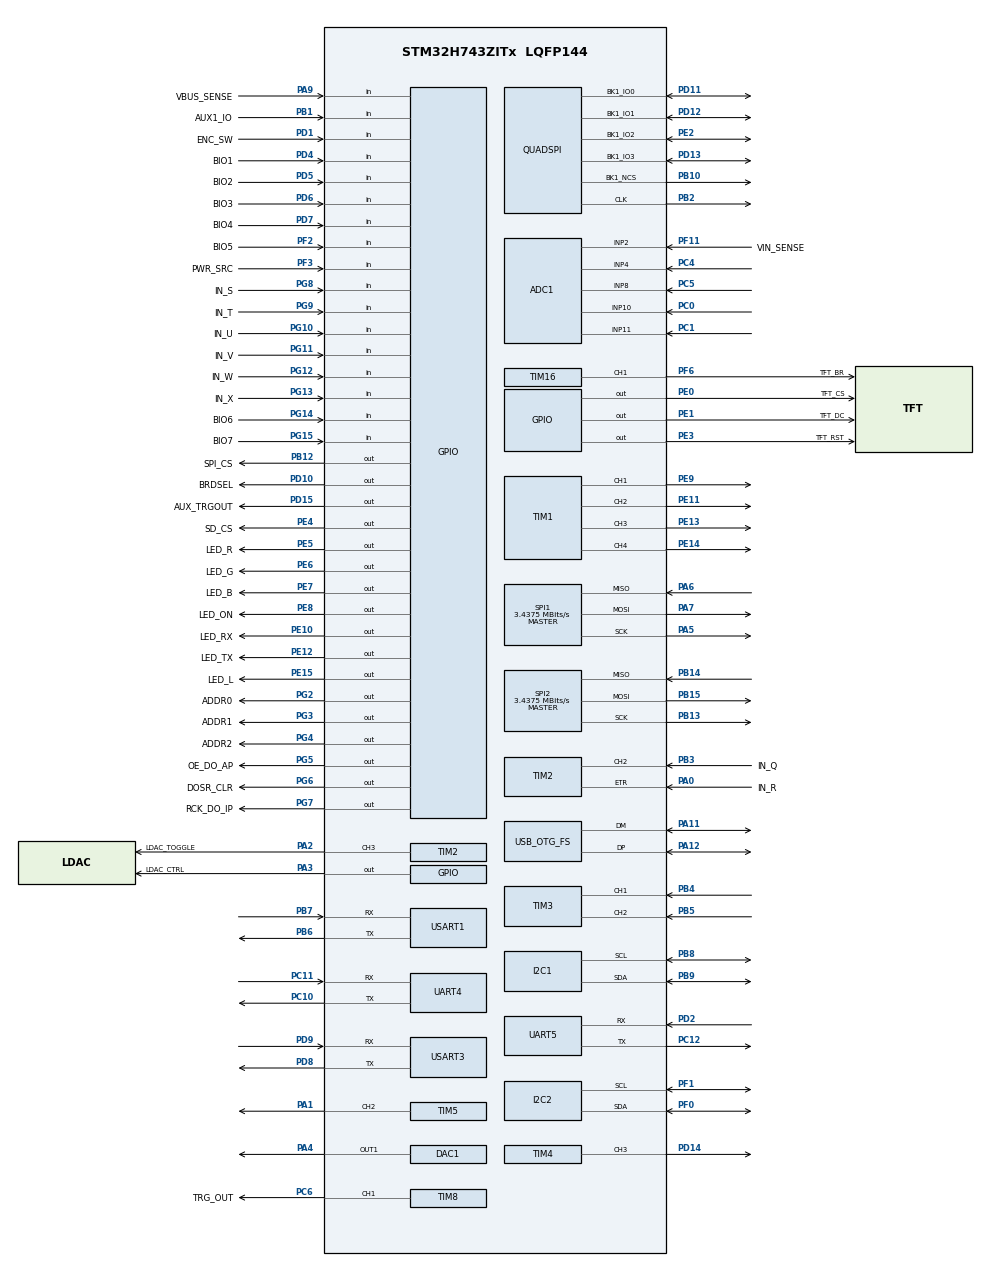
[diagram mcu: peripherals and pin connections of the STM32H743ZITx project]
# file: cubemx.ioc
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ADC1.Channel-1\#ChannelRegularConversion=ADC_CHANNEL_10
ADC1.Channel-2\#ChannelRegularConversion=ADC_CHANNEL_11
ADC1.Channel-3\#ChannelRegularConversion=ADC_CHANNEL_4
ADC1.Channel-4\#ChannelRegularConversion=ADC_CHANNEL_8
ADC1.Channel-5\#ChannelRegularConversion=ADC_CHANNEL_2
ADC1.NbrOfConversion=5
ADC1.NbrOfConversionFlag=1
ADC1.OffsetNumber-1\#ChannelRegularConversion=ADC_OFFSET_NONE
ADC1.OffsetNumber-2\#ChannelRegularConversion=ADC_OFFSET_NONE
ADC1.OffsetNumber-3\#ChannelRegularConversion=ADC_OFFSET_NONE
ADC1.OffsetNumber-4\#ChannelRegularConversion=ADC_OFFSET_NONE
ADC1.OffsetNumber-5\#ChannelRegularConversion=ADC_OFFSET_NONE
ADC1.OffsetSignedSaturation-1\#ChannelRegularConversion=DISABLE
ADC1.OffsetSignedSaturation-2\#ChannelRegularConversion=DISABLE
ADC1.OffsetSignedSaturation-3\#ChannelRegularConversion=DISABLE
ADC1.OffsetSignedSaturation-4\#ChannelRegularConversion=DISABLE
ADC1.OffsetSignedSaturation-5\#ChannelRegularConversion=DISABLE
ADC1.Rank-1\#ChannelRegularConversion=1
ADC1.Rank-2\#ChannelRegularConversion=2
ADC1.Rank-3\#ChannelRegularConversion=3
ADC1.Rank-4\#ChannelRegularConversion=4
ADC1.Rank-5\#ChannelRegularConversion=5
ADC1.SamplingTime-1\#ChannelRegularConversion=ADC_SAMPLETIME_1CYCLE_5
ADC1.SamplingTime-2\#ChannelRegularConversion=ADC_SAMPLETIME_1CYCLE_5
ADC1.SamplingTime-3\#ChannelRegularConversion=ADC_SAMPLETIME_1CYCLE_5
ADC1.SamplingTime-4\#ChannelRegularConversion=ADC_SAMPLETIME_1CYCLE_5
ADC1.SamplingTime-5\#ChannelRegularConversion=ADC_SAMPLETIME_64CYCLES_5
ADC1.master=1
CORTEX_M7.default_mode_Activation=1
DAC1.DAC_Channel-DAC_OUT1=DAC_CHANNEL_1
Dma.ADC1.0.Direction=DMA_PERIPH_TO_MEMORY
Dma.ADC1.0.EventEnable=DISABLE
Dma.ADC1.0.FIFOMode=DMA_FIFOMODE_DISABLE
Dma.ADC1.0.Instance=DMA1_Stream0
Dma.ADC1.0.MemDataAlignment=DMA_MDATAALIGN_HALFWORD
Dma.ADC1.0.MemInc=DMA_MINC_ENABLE
Dma.ADC1.0.Mode=DMA_CIRCULAR
Dma.ADC1.0.PeriphDataAlignment=DMA_PDATAALIGN_HALFWORD
Dma.ADC1.0.PeriphInc=DMA_PINC_DISABLE
Dma.ADC1.0.Polarity=HAL_DMAMUX_REQ_GEN_RISING
Dma.ADC1.0.Priority=DMA_PRIORITY_LOW
Dma.ADC1.0.RequestNumber=1
Dma.ADC1.0.SignalID=NONE
Dma.ADC1.0.SyncEnable=DISABLE
Dma.ADC1.0.SyncPolarity=HAL_DMAMUX_SYNC_NO_EVENT
Dma.ADC1.0.SyncRequestNumber=1
Dma.ADC1.0.SyncSignalID=NONE
Dma.Request0=ADC1
I2C1.Timing=0x40505681
I2C2.Timing=0x40505681
Mcu.Family=STM32H7
Mcu.Name=STM32H743ZITx
Mcu.Package=LQFP144
NVIC.DMA1_Stream0_IRQn=true\:0\:0\:false\:false\:true\:false\:true\:true
NVIC.OTG_FS_IRQn=true\:0\:0\:false\:false\:true\:false\:true\:true
NVIC.PriorityGroup=NVIC_PRIORITYGROUP_4
PA0.GPIO_Label=IN_R
PA0.Signal=S_TIM2_CH1_ETR
PA1.Signal=S_TIM5_CH2
PA11.Mode=Device_Only
PA11.Signal=USB_OTG_FS_DM
PA12.Mode=Device_Only
PA12.Signal=USB_OTG_FS_DP
PA13\ (JTMS/SWDIO).Mode=Serial_Wire
PA13\ (JTMS/SWDIO).Signal=DEBUG_JTMS-SWDIO
PA14\ (JTCK/SWCLK).Mode=Serial_Wire
PA14\ (JTCK/SWCLK).Signal=DEBUG_JTCK-SWCLK
PA2.GPIO_Label=LDAC_TOGGLE
PA2.Signal=S_TIM2_CH3
PA3.GPIO_Label=LDAC_CTRL
PA3.Signal=GPIO_Output
PA4.Signal=COMP_DAC11_group
PA5.Mode=Full_Duplex_Master
PA5.Signal=SPI1_SCK
PA6.Mode=Full_Duplex_Master
PA6.Signal=SPI1_MISO
PA7.Mode=Full_Duplex_Master
PA7.Signal=SPI1_MOSI
PA9.GPIO_Label=VBUS_SENSE
PA9.Signal=GPIO_Input
PB1.GPIO_Label=AUX1_IO
PB1.Signal=GPIO_Input
PB10.Mode=Single Bank 1
PB10.Signal=QUADSPI_BK1_NCS
PB12.GPIO_Label=SPI_CS
PB12.Signal=GPIO_Output
PB13.Mode=Full_Duplex_Master
PB13.Signal=SPI2_SCK
PB14.Mode=Full_Duplex_Master
PB14.Signal=SPI2_MISO
PB15.Mode=Full_Duplex_Master
PB15.Signal=SPI2_MOSI
PB2.Mode=Single Bank 1
PB2.Signal=QUADSPI_CLK
PB3\ (JTDO/TRACESWO).GPIO_Label=IN_Q
PB3\ (JTDO/TRACESWO).Signal=S_TIM2_CH2
PB4\ (NJTRST).Signal=S_TIM3_CH1
PB5.Signal=S_TIM3_CH2
PB6.Mode=Asynchronous
PB6.Signal=USART1_TX
PB7.Mode=Asynchronous
PB7.Signal=USART1_RX
PB8.Mode=I2C
PB8.Signal=I2C1_SCL
PB9.Mode=I2C
PB9.Signal=I2C1_SDA
PC0.Signal=ADCx_INP10
PC1.Signal=ADCx_INP11
PC10.Mode=Asynchronous
PC10.Signal=UART4_TX
PC11.Mode=Asynchronous
PC11.Signal=UART4_RX
PC12.Mode=Asynchronous
PC12.Signal=UART5_TX
PC14-OSC32_IN\ (OSC32_IN).Mode=LSE-External-Oscillator
PC14-OSC32_IN\ (OSC32_IN).Signal=RCC_OSC32_IN
PC15-OSC32_OUT\ (OSC32_OUT).Mode=LSE-External-Oscillator
PC15-OSC32_OUT\ (OSC32_OUT).Signal=RCC_OSC32_OUT
PC4.Signal=ADCx_INP4
PC5.Signal=ADCx_INP8
PC6.GPIO_Label=TRG_OUT
PC6.Signal=S_TIM8_CH1
PD1.GPIO_Label=ENC_SW
PD1.GPIO_PuPd=GPIO_PULLUP
PD1.Signal=GPIO_Input
PD10.GPIO_Label=BRDSEL
PD10.Signal=GPIO_Output
PD11.Mode=Single Bank 1
PD11.Signal=QUADSPI_BK1_IO0
PD12.Mode=Single Bank 1
PD12.Signal=QUADSPI_BK1_IO1
PD13.Mode=Single Bank 1
PD13.Signal=QUADSPI_BK1_IO3
PD14.Signal=S_TIM4_CH3
PD15.GPIO_Label=AUX_TRGOUT
PD15.Signal=GPIO_Output
PD2.Mode=Asynchronous
PD2.Signal=UART5_RX
PD4.GPIO_Label=BIO1
PD4.Signal=GPIO_Input
PD5.GPIO_Label=BIO2
PD5.Signal=GPIO_Input
PD6.GPIO_Label=BIO3
PD6.Signal=GPIO_Input
PD7.GPIO_Label=BIO4
PD7.Signal=GPIO_Input
PD8.Mode=Asynchronous
PD8.Signal=USART3_TX
PD9.Mode=Asynchronous
PD9.Signal=USART3_RX
PE0.GPIO_Label=TFT_CS
PE0.Signal=GPIO_Output
PE1.GPIO_Label=TFT_DC
PE1.Signal=GPIO_Output
PE10.GPIO_Label=LED_RX
PE10.Signal=GPIO_Output
PE11.Signal=S_TIM1_CH2
PE12.GPIO_Label=LED_TX
PE12.Signal=GPIO_Output
PE13.Signal=S_TIM1_CH3
PE14.Signal=S_TIM1_CH4
PE15.GPIO_Label=LED_L
PE15.Signal=GPIO_Output
PE2.Mode=Single Bank 1
PE2.Signal=QUADSPI_BK1_IO2
PE3.GPIO_Label=TFT_RST
PE3.Signal=GPIO_Output
PE4.GPIO_Label=SD_CS
PE4.Signal=GPIO_Output
PE5.GPIO_Label=LED_R
PE5.Signal=GPIO_Output
PE6.GPIO_Label=LED_G
PE6.Signal=GPIO_Output
PE7.GPIO_Label=LED_B
PE7.Signal=GPIO_Output
PE8.GPIO_Label=LED_ON
PE8.Signal=GPIO_Output
PE9.Signal=S_TIM1_CH1
PF0.Mode=I2C
PF0.Signal=I2C2_SDA
PF1.Mode=I2C
PF1.Signal=I2C2_SCL
PF11.GPIO_Label=VIN_SENSE
PF11.Mode=IN2-Single-Ended
PF11.Signal=ADC1_INP2
PF2.GPIO_Label=BIO5
PF2.Signal=GPIO_Input
PF3.GPIO_Label=PWR_SRC
PF3.Signal=GPIO_Input
PF6.GPIO_Label=TFT_BR
PF6.Signal=S_TIM16_CH1
PG10.GPIO_Label=IN_U
PG10.Signal=GPIO_Input
PG11.GPIO_Label=IN_V
PG11.Signal=GPIO_Input
PG12.GPIO_Label=IN_W
PG12.Signal=GPIO_Input
PG13.GPIO_Label=IN_X
PG13.Signal=GPIO_Input
PG14.GPIO_Label=BIO6
PG14.Signal=GPIO_Input
PG15.GPIO_Label=BIO7
PG15.Signal=GPIO_Input
PG2.GPIO_Label=ADDR0
PG2.Signal=GPIO_Output
PG3.GPIO_Label=ADDR1
PG3.Signal=GPIO_Output
PG4.GPIO_Label=ADDR2
PG4.Signal=GPIO_Output
PG5.GPIO_Label=OE_DO_AP
PG5.Signal=GPIO_Output
PG6.GPIO_Label=DOSR_CLR
PG6.Signal=GPIO_Output
PG7.GPIO_Label=RCK_DO_IP
PG7.Signal=GPIO_Output
PG8.GPIO_Label=IN_S
PG8.Signal=GPIO_Input
PG9.GPIO_Label=IN_T
PG9.Signal=GPIO_Input
PH0-OSC_IN\ (PH0).Mode=HSE-External-Oscillator
PH0-OSC_IN\ (PH0).Signal=RCC_OSC_IN
PH1-OSC_OUT\ (PH1).Mode=HSE-External-Oscillator
PH1-OSC_OUT\ (PH1).Signal=RCC_OSC_OUT
ProjectManager.HeapSize=0x200
ProjectManager.StackSize=0x400
ProjectManager.TargetToolchain=Makefile
RCC.ADCFreq_Value=100000000
RCC.APB1Freq_Value=110000000
RCC.APB2Freq_Value=110000000
RCC.APB3Freq_Value=110000000
RCC.APB4Freq_Value=110000000
RCC.CortexFreq_Value=440000000
RCC.D1PPRE=RCC_APB3_DIV2
RCC.D2PPRE1=RCC_APB1_DIV2
RCC.D2PPRE2=RCC_APB2_DIV2
RCC.D3PPRE=RCC_APB4_DIV2
RCC.DIVM1=5
RCC.DIVM2=5
RCC.DIVM3=5
RCC.DIVN1=176
RCC.DIVN2=80
RCC.DIVN3=96
RCC.DIVP2=4
RCC.DIVQ1=8
RCC.DIVQ2=4
RCC.DIVQ3=10
RCC.DIVR2=4
RCC.EnbaleCSS=true
RCC.HCLKFreq_Value=220000000
RCC.HPRE=RCC_HCLK_DIV2
RCC.PLLFRACN=0
RCC.PLLSourceVirtual=RCC_PLLSOURCE_HSE
RCC.RTCClockSelection=RCC_RTCCLKSOURCE_LSE
RCC.SYSCLKFreq_VALUE=440000000
RCC.SYSCLKSource=RCC_SYSCLKSOURCE_PLLCLK
RCC.SupplySource=PWR_LDO_SUPPLY
RCC.USBCLockSelection=RCC_USBCLKSOURCE_PLL3
RCC.USBFreq_Value=48000000
SH.ADCx_INP10.0=ADC1_INP10,IN10-Single-Ended
SH.ADCx_INP11.0=ADC1_INP11,IN11-Single-Ended
SH.ADCx_INP4.0=ADC1_INP4,IN4-Single-Ended
SH.ADCx_INP8.0=ADC1_INP8,IN8-Single-Ended
SH.COMP_DAC11_group.0=DAC1_OUT1,DAC_OUT1
SH.S_TIM16_CH1.0=TIM16_CH1,PWM Generation1 CH1
SH.S_TIM1_CH1.0=TIM1_CH1,PWM Generation1 CH1
SH.S_TIM1_CH2.0=TIM1_CH2,PWM Generation2 CH2
SH.S_TIM1_CH3.0=TIM1_CH3,PWM Generation3 CH3
SH.S_TIM1_CH4.0=TIM1_CH4,PWM Generation4 CH4
SH.S_TIM2_CH1_ETR.0=TIM2_ETR,TriggerSource_ETR
SH.S_TIM2_CH2.0=TIM2_CH2,Input_Capture2_from_TI2
SH.S_TIM2_CH3.0=TIM2_CH3,Output Compare3 CH3
SH.S_TIM3_CH1.0=TIM3_CH1,Encoder_Interface
SH.S_TIM3_CH2.0=TIM3_CH2,Encoder_Interface
SH.S_TIM4_CH3.0=TIM4_CH3,Output Compare3 CH3
SH.S_TIM5_CH2.0=TIM5_CH2,Output Compare2 CH2
SH.S_TIM8_CH1.0=TIM8_CH1,Output Compare1 CH1
SPI1.BaudRatePrescaler=SPI_BAUDRATEPRESCALER_32
SPI1.CalculateBaudRate=3.4375 MBits/s
SPI1.Direction=SPI_DIRECTION_2LINES
SPI1.Mode=SPI_MODE_MASTER
SPI1.VirtualType=VM_MASTER
SPI2.BaudRatePrescaler=SPI_BAUDRATEPRESCALER_32
SPI2.CalculateBaudRate=3.4375 MBits/s
SPI2.Direction=SPI_DIRECTION_2LINES
SPI2.Mode=SPI_MODE_MASTER
SPI2.VirtualType=VM_MASTER
TIM1.Channel-PWM\ Generation1\ CH1=TIM_CHANNEL_1
TIM1.Channel-PWM\ Generation2\ CH2=TIM_CHANNEL_2
TIM1.Channel-PWM\ Generation3\ CH3=TIM_CHANNEL_3
TIM1.Channel-PWM\ Generation4\ CH4=TIM_CHANNEL_4
TIM16.Channel=TIM_CHANNEL_1
TIM2.Channel-Input_Capture2_from_TI2=TIM_CHANNEL_2
TIM2.Channel-Output\ Compare3\ CH3=TIM_CHANNEL_3
TIM4.Channel-Output\ Compare3\ CH3=TIM_CHANNEL_3
TIM5.Channel-Output\ Compare2\ CH2=TIM_CHANNEL_2
TIM8.Channel-Output\ Compare1\ CH1=TIM_CHANNEL_1
USART1.VirtualMode-Asynchronous=VM_ASYNC
USART3.VirtualMode-Asynchronous=VM_ASYNC
USB_DEVICE.CLASS_NAME_FS=CDC
USB_DEVICE.VirtualMode-CDC_FS=Cdc
USB_DEVICE.VirtualModeFS=Cdc_FS
USB_OTG_FS.VirtualMode=Device_Only
VP_MEMORYMAP_VS_MEMORYMAP.Mode=CurAppReg
VP_RTC_VS_RTC_Activate.Mode=RTC_Enabled
VP_RTC_VS_RTC_Calendar.Mode=RTC_Calendar
VP_TIM16_VS_ClockSourceINT.Mode=Enable_Timer
VP_TIM1_VS_ClockSourceINT.Mode=Internal
VP_TIM2_VS_ClockSourceINT.Mode=Internal
VP_TIM2_VS_ControllerModeReset.Mode=Reset Mode
VP_TIM4_VS_ClockSourceINT.Mode=Internal
VP_TIM5_VS_ClockSourceINT.Mode=Internal
VP_TIM7_VS_ClockSourceINT.Mode=Enable_Timer
VP_TIM8_VS_ClockSourceINT.Mode=Internal
VP_USB_DEVICE_VS_USB_DEVICE_CDC_FS.Mode=CDC_FS
board=custom

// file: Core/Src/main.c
/* USER CODE BEGIN Header */
/**
  ******************************************************************************
  * @file           : main.c
  * @brief          : Main program body
  ******************************************************************************
  * @attention
  *
  * Copyright (c) 2026 STMicroelectronics.
  * All rights reserved.
  *
  * This software is licensed under terms that can be found in the LICENSE file
  * in the root directory of this software component.
  * If no LICENSE file comes with this software, it is provided AS-IS.
  *
  ******************************************************************************
  */
/* USER CODE END Header */
#include "main.h"
#include "adc.h"
#include "dac.h"
#include "dma.h"
#include "i2c.h"
#include "quadspi.h"
#include "rtc.h"
#include "spi.h"
#include "tim.h"
#include "usart.h"
#include "usb_device.h"
#include "gpio.h"

/* USER CODE BEGIN Includes */
#include "app.h"
/* USER CODE END Includes */

void SystemClock_Config(void);
static void MPU_Config(void);

int main(void)
{

  /* MPU Configuration--------------------------------------------------------*/
  MPU_Config();

  /* MCU Configuration--------------------------------------------------------*/

  /* Reset of all peripherals, Initializes the Flash interface and the Systick. */
  HAL_Init();

  /* Configure the system clock */
  SystemClock_Config();

  /* Initialize all configured peripherals */
  MX_GPIO_Init();
  MX_DMA_Init();
  MX_ADC1_Init();
  MX_DAC1_Init();
  MX_I2C1_Init();
  MX_I2C2_Init();
  MX_QUADSPI_Init();
  MX_SPI1_Init();
  MX_SPI2_Init();
  MX_TIM1_Init();
  MX_TIM2_Init();
  MX_TIM3_Init();
  MX_TIM4_Init();
  MX_TIM5_Init();
  MX_TIM7_Init();
  MX_TIM8_Init();
  MX_UART4_Init();
  MX_UART5_Init();
  MX_USART1_UART_Init();
  MX_USART3_UART_Init();
  MX_RTC_Init();
  MX_TIM16_Init();
  MX_USB_DEVICE_Init();
  /* USER CODE BEGIN 2 */
  appSetup();
  /* USER CODE END 2 */

  /* Infinite loop */
  while (1)
  {

  }
}

void SystemClock_Config(void)
{
  RCC_OscInitTypeDef RCC_OscInitStruct = {0};
  RCC_ClkInitTypeDef RCC_ClkInitStruct = {0};

  /** Supply configuration update enable
  */
  HAL_PWREx_ConfigSupply(PWR_LDO_SUPPLY);

  /** Configure the main internal regulator output voltage
  */
  __HAL_PWR_VOLTAGESCALING_CONFIG(PWR_REGULATOR_VOLTAGE_SCALE0);

  while(!__HAL_PWR_GET_FLAG(PWR_FLAG_VOSRDY)) {}

  /** Configure LSE Drive Capability
  */
  HAL_PWR_EnableBkUpAccess();
  __HAL_RCC_LSEDRIVE_CONFIG(RCC_LSEDRIVE_LOW);

  /** Initializes the RCC Oscillators according to the specified parameters
  * in the RCC_OscInitTypeDef structure.
  */
  RCC_OscInitStruct.OscillatorType = RCC_OSCILLATORTYPE_HSE|RCC_OSCILLATORTYPE_LSE;
  RCC_OscInitStruct.HSEState = RCC_HSE_ON;
  RCC_OscInitStruct.LSEState = RCC_LSE_ON;
  RCC_OscInitStruct.PLL.PLLState = RCC_PLL_ON;
  RCC_OscInitStruct.PLL.PLLSource = RCC_PLLSOURCE_HSE;
  RCC_OscInitStruct.PLL.PLLM = 5;
  RCC_OscInitStruct.PLL.PLLN = 176;
  RCC_OscInitStruct.PLL.PLLP = 2;
  RCC_OscInitStruct.PLL.PLLQ = 8;
  RCC_OscInitStruct.PLL.PLLR = 2;
  RCC_OscInitStruct.PLL.PLLRGE = RCC_PLL1VCIRANGE_2;
  RCC_OscInitStruct.PLL.PLLVCOSEL = RCC_PLL1VCOWIDE;
  RCC_OscInitStruct.PLL.PLLFRACN = 0;
  if (HAL_RCC_OscConfig(&RCC_OscInitStruct) != HAL_OK)
  {
    Error_Handler();
  }

  /** Initializes the CPU, AHB and APB buses clocks
  */
  RCC_ClkInitStruct.ClockType = RCC_CLOCKTYPE_HCLK|RCC_CLOCKTYPE_SYSCLK
                              |RCC_CLOCKTYPE_PCLK1|RCC_CLOCKTYPE_PCLK2
                              |RCC_CLOCKTYPE_D3PCLK1|RCC_CLOCKTYPE_D1PCLK1;
  RCC_ClkInitStruct.SYSCLKSource = RCC_SYSCLKSOURCE_PLLCLK;
  RCC_ClkInitStruct.SYSCLKDivider = RCC_SYSCLK_DIV1;
  RCC_ClkInitStruct.AHBCLKDivider = RCC_HCLK_DIV2;
  RCC_ClkInitStruct.APB3CLKDivider = RCC_APB3_DIV2;
  RCC_ClkInitStruct.APB1CLKDivider = RCC_APB1_DIV2;
  RCC_ClkInitStruct.APB2CLKDivider = RCC_APB2_DIV2;
  RCC_ClkInitStruct.APB4CLKDivider = RCC_APB4_DIV2;

  if (HAL_RCC_ClockConfig(&RCC_ClkInitStruct, FLASH_LATENCY_3) != HAL_OK)
  {
    Error_Handler();
  }

  /** Enables the Clock Security System
  */
  HAL_RCC_EnableCSS();
}

 /* MPU Configuration */

void MPU_Config(void)
{
  MPU_Region_InitTypeDef MPU_InitStruct = {0};

  /* Disables the MPU */
  HAL_MPU_Disable();

  /** Initializes and configures the Region and the memory to be protected
  */
  MPU_InitStruct.Enable = MPU_REGION_ENABLE;
  MPU_InitStruct.Number = MPU_REGION_NUMBER0;
  MPU_InitStruct.BaseAddress = 0x0;
  MPU_InitStruct.Size = MPU_REGION_SIZE_4GB;
  MPU_InitStruct.SubRegionDisable = 0x87;
  MPU_InitStruct.TypeExtField = MPU_TEX_LEVEL0;
  MPU_InitStruct.AccessPermission = MPU_REGION_NO_ACCESS;
  MPU_InitStruct.DisableExec = MPU_INSTRUCTION_ACCESS_DISABLE;
  MPU_InitStruct.IsShareable = MPU_ACCESS_SHAREABLE;
  MPU_InitStruct.IsCacheable = MPU_ACCESS_NOT_CACHEABLE;
  MPU_InitStruct.IsBufferable = MPU_ACCESS_NOT_BUFFERABLE;

  HAL_MPU_ConfigRegion(&MPU_InitStruct);
  /* Enables the MPU */
  HAL_MPU_Enable(MPU_PRIVILEGED_DEFAULT);

}

void Error_Handler(void)
{
  __disable_irq();
  while (1)
  {
  }
}
